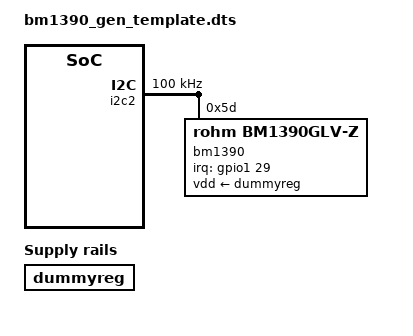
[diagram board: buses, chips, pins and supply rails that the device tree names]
/dts-v1/;
/plugin/;

/{ /* this is our device tree overlay root node */

	compatible = "ti,beaglebone", "ti,beaglebone-black";
	part-number = "BBB-I2C1"; // you can choose any name here but it should be memorable
 	version = "00A0";

    fragment@1 {
        target-path = "/";
        __overlay__ {
            dummyreg: dummyreg {
                compatible = "regulator-fixed";
                regulator-name = "dummy-vdd";
            };
        };
    };

    fragment@2 {
        target = <&i2c2>;

        __overlay__ {
            clock-frequency = <100000>;

            bm1390: bm1390@5d {
                    reg = <0x5d>;
                    compatible = "rohm,bm1390glv-z";
                    interrupt-parent = <&gpio1>;
                    interrupts = <29 8>;
                    vdd-supply = <&dummyreg>;
            };
        };
    };

}; /* root node end */
